# nrf54h20_enga_application register map
Vendor: Nordic Semiconductor; Series: nRF54h; File version: 1
CPU: CM33 r0p4, little endian, MPU, FPU, 3 interrupt priority bits, 480 interrupts, 4 SAU regions
Registers are 32-bit, read-write, reset 0x0 unless marked. A register's access mark holds for its fields unless they carry their own. Offsets are from the block's base; [hi:lo] are bit positions; lines under a group give offsets from that group; {n}, {i} and the like mark numbered series; 'fields as' and 'values as' point back to an identical list.

## ICACHEDATA_S — CACHEDATA 0
Base 0x12F00000
Same registers: DCACHEDATA_S 0x32F00000
{0x0+0x40*i} SET[{i}] (i=0..255) group — Unspecified
  {0x0+0x20*j} WAY[{j}] (j=0..1) group — Unspecified
    {0x0+8k} DU[{k}] (k=0..3) group — Unspecified
      {0x0+4l} DATA[{l}] (l=0..1) — Description collection: Cache data bits for DATA[q] in DU[p] (DataUnit) of SET[n], WAY[o].
        [31:0] Data ro

## ICACHEINFO_S — CACHEINFO 0
Base 0x12F10000
Same registers: DCACHEINFO_S 0x32F10000
{0x0+8i} SET[{i}] (i=0..255) group — Unspecified
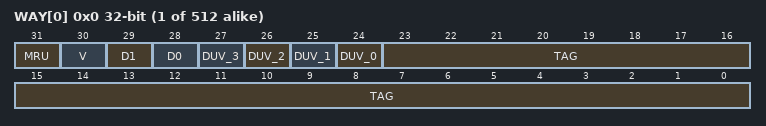
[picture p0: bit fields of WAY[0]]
  {0x0+4j} WAY[{j}] (j=0..1) — Description collection: Cache information for SET[n], WAY[o].
    [31] MRU ro — Most recently used way.
      0=Way0 was most recently used; 1=Way1 was most recently used
    [30] V ro — Line valid bit.
      0=Invalid cache line; 1=Valid cache line
    [29] D1 ro — Dirty data unit 1.
      0=Clean data unit; 1=Dirty data unit
    [28] D0 ro — Dirty data unit 0.
      0=Clean data unit; 1=Dirty data unit
    [n+24] DUV_{n} ro (n=0..3) — Data unit valid info.
      0=Invalid data unit; 1=Valid data unit
    [23:0] TAG ro — Cache tag.

## GLOBAL_STMDATA_NS — System Trace Macrocell data buffer 0
Base 0xA0000000
Same registers: GLOBAL_STMDATA_S 0xA0000000 (alternate view of GLOBAL_STMDATA_NS)
{0x0+0x2000000*i} DOMAIN[{i}] (i=0..15) group — Unspecified
  {0x0+j} NSDATA[{j}] (j=0..16777215) 8-bit — Description collection: NonSecure STM output data buffer for domain n. Writes to this region generates trace packets with id n+96.
  {0x1000000+j} SDATA[{j}] (j=0..16777215) 8-bit — Description collection: Secure STM output data buffer for domain n. Writes to this region generates trace packets with id n+32.
{0x0+0x1000000*i} BUFFER[{i}] (i=0..15) group (alternate view of DOMAIN[{i}]) — Raw buffer access to STM array. Use when DOMAIN array does not apply.
  {0x0+j} DATA[{j}] (j=0..16777215) 8-bit — Description collection: STM output data buffer n. Writes to this region generates trace packets.

## GLOBAL_TDDCONF_NS — TDDCONF 0
Base 0xBF001000
Same registers: GLOBAL_TDDCONF_S 0xBF001000 (alternate view of GLOBAL_TDDCONF_NS)
0x400 SYSPWRUPREQ — System power-up request
  [0] ACTIVE — Activate power-up request
    0=NotActive (Power-up request not active); 1=Active (Power-up request active)
0x404 DBGPWRUPREQ — Debug power-up request
  fields as SYSPWRUPREQ
0x408 TRACEPORTSPEED — Trace port trace clock speed
  [1:0] SPEED — Trace clock speed
    0=Speed25MHz; 1=Speed12500KHz (Speed 12.5MHz); 2=Speed6250KHz (Speed 6.25MHz); 3=Speed3125KHz (Speed 3.125MHz)
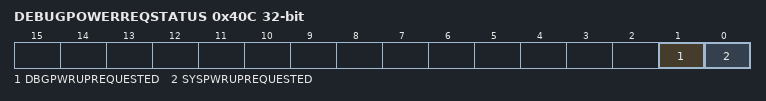
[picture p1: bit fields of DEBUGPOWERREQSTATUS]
0x40C DEBUGPOWERREQSTATUS ro — Combined effective system status of both SWJ-DP and TDDCONF registers originated power requests
  [1] DBGPWRUPREQUESTED — Debug domain powerup request status
    0=NoPowerReq (Power not requested); 1=Power requested
  [0] SYSPWRUPREQUESTED — System powerup request status
    0=NoPowerReq (Power not requested); 1=Power requested

## GLOBAL_TSGEN_NS — Timestamp generator
Base 0xBF041000
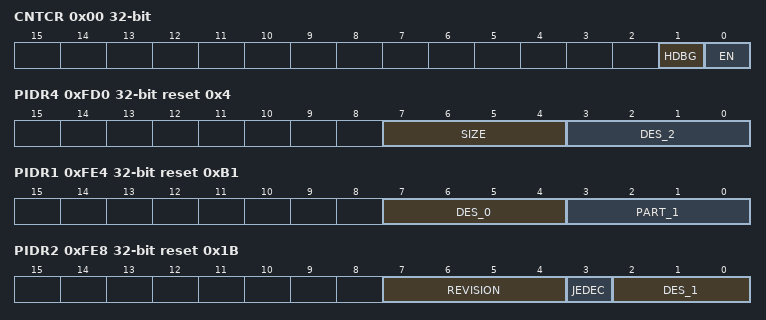
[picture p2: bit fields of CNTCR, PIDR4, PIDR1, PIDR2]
0x00 CNTCR — Counter Control Register
  [1] HDBG — Halt on Debug
    0=Disabled (Do not halt on debug, HLTDBG signal into the counter has no effect.); 1=Enabled (Halt on debug, when HLTDBG is driven HIGH, the count value is held static.)
  [0] EN — Counter enable
    0=Disabled (Unspecified); 1=Enabled (Unspecified)
0x04 CNTSR ro — Counter Status Register
  [1] DBGH — Debug halted
0x08 CNTCVL — Current Counter Value Lower register
  [31:0] CNTCVL_L_32 — Current value of Counter, lower 32 bits
0x0C CNTCVU — Current Counter Value Upper register
  [31:0] CNTCVU_U_32 — Current value of Counter, upper 32 bits
0x20 CNTFID0 — Base Frequency ID
  [31:0] FREQ — Frequency in number of ticks per second (up to 4 GHz)
0xFD0 PIDR4 ro reset 0x4 — Peripheral ID4 Register
  [7:4] SIZE — This is a 4-bit value that indicates the total contiguous size of the memory window used by this component in powers of 2 from the standard 4KB. If a component only requires the standard 4KB, this must read as 0x0, 4KB only. For 8KB set to 0x1, for 16KB set to 0x2, for 32KB set to 0x3, and so on.
  [3:0] DES_2 — JEDEC continuation code indicating the designer of the component, together with the identity code.
0xFE0 PIDR0 ro reset 0x1 — Peripheral ID0 Register
  [7:0] PART_0 — Bits [7:0] of the component part number. This is selected by the designer of the component.
0xFE4 PIDR1 ro reset 0xB1 — Peripheral ID1 Register
  [7:4] DES_0 — Bits [3:0] of the JEDEC identity code indicating the designer of the component, together with the continuation code.
  [3:0] PART_1 — Bits [11:8] of the component part number. This is selected by the designer of the component.
0xFE8 PIDR2 ro reset 0x1B — Peripheral ID2 Register
  [7:4] REVISION — The Revision field is an incremental value starting at 0x0 for the first design of this component. This only increases by 1 for both major and minor revisions and is used as a look-up to establish the exact major and minor revision.
  [3] JEDEC — Always set. Indicates that a JEDEC assigned value is used.
  [2:0] DES_1 — Bits [6:4] of the JEDEC identity code indicating the designer of the component, together with the continuation code.
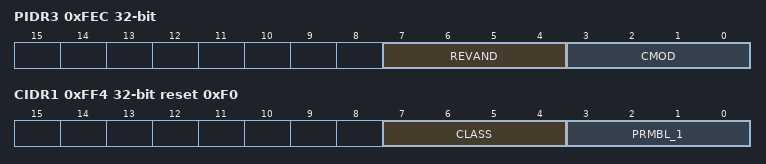
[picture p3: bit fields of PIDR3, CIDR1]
0xFEC PIDR3 ro — Peripheral ID3 Register
  [7:4] REVAND — This field indicates minor errata fixes specific to this design, for example metal fixes after implementation. In most cases this field is zero. It is recommended that component designers ensure this field can be changed by a metal fix if required, for example by driving it from registers that reset to zero.
  [3:0] CMOD — Where the component is reusable IP, this value indicates if the customer has modified the behavior of the component. In most cases this field is zero.
0xFF0 CIDR0 ro reset 0xD — Component ID0 Register
  [7:0] PRMBL_0 — Contains bits[7:0] of the component identification code.
0xFF4 CIDR1 ro reset 0xF0 — Component ID1 Register
  [7:4] CLASS — Class of the component, for example, ROM table or CoreSight component.
  [3:0] PRMBL_1 — Contains bits[11:8] of the component identification code.
0xFF8 CIDR2 ro reset 0x5 — Component ID2 Register
  [7:0] PRMBL_2 — Contains bits[23:16] of the component identification code.
0xFFC CIDR3 ro reset 0xB1 — Component ID3 Register
  [7:0] PRMBL_3 — Contains bits[31:24] of the component identification code.
